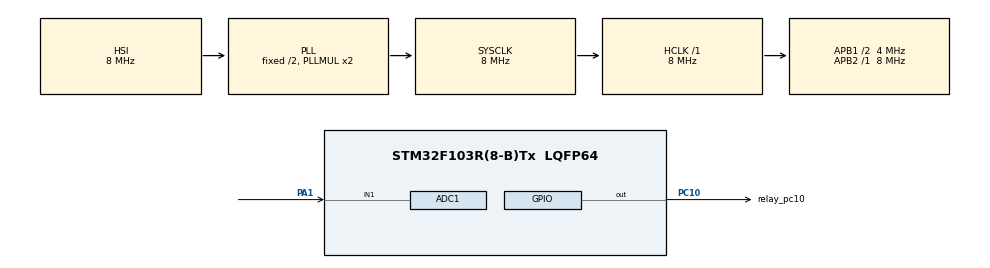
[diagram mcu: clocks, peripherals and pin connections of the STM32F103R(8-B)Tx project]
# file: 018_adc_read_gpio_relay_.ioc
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ADC1.Channel-0\#ChannelRegularConversion=ADC_CHANNEL_1
ADC1.NbrOfConversionFlag=1
ADC1.Rank-0\#ChannelRegularConversion=1
ADC1.SamplingTime-0\#ChannelRegularConversion=ADC_SAMPLETIME_1CYCLE_5
ADC1.master=1
Mcu.Family=STM32F1
Mcu.Name=STM32F103R(8-B)Tx
Mcu.Package=LQFP64
NVIC.PriorityGroup=NVIC_PRIORITYGROUP_4
PA1.Signal=ADCx_IN1
PA13.GPIO_Label=TMS
PA13.Mode=Serial_Wire
PA13.Signal=SYS_JTMS-SWDIO
PA14.GPIO_Label=TCK
PA14.Mode=Serial_Wire
PA14.Signal=SYS_JTCK-SWCLK
PB3.GPIO_Label=SWO
PB3.Signal=SYS_JTDO-TRACESWO
PC10.GPIO_Label=relay_pc10
PC10.GPIO_ModeDefaultOutputPP=GPIO_MODE_OUTPUT_OD
PC10.GPIO_PuPd=GPIO_NOPULL
PC10.Signal=GPIO_Output
PC14-OSC32_IN.Mode=LSE-External-Oscillator
PC14-OSC32_IN.Signal=RCC_OSC32_IN
PC15-OSC32_OUT.Mode=LSE-External-Oscillator
PC15-OSC32_OUT.Signal=RCC_OSC32_OUT
PD0-OSC_IN.Mode=HSE-External-Clock-Source
PD0-OSC_IN.Signal=RCC_OSC_IN
PD1-OSC_OUT.Mode=HSE-External-Clock-Source
PD1-OSC_OUT.Signal=RCC_OSC_OUT
ProjectManager.HeapSize=0x200
ProjectManager.StackSize=0x400
ProjectManager.TargetToolchain=STM32CubeIDE
RCC.AHBFreq_Value=8000000
RCC.APB1CLKDivider=RCC_HCLK_DIV2
RCC.APB1Freq_Value=4000000
RCC.APB1TimFreq_Value=8000000
RCC.APB2Freq_Value=8000000
RCC.APB2TimFreq_Value=8000000
RCC.HCLKFreq_Value=8000000
RCC.RTCClockSelection=RCC_RTCCLKSOURCE_LSE
RCC.SYSCLKFreq_VALUE=8000000
RCC.SYSCLKSource=RCC_SYSCLKSOURCE_PLLCLK
RCC.USBFreq_Value=8000000
SH.ADCx_IN1.0=ADC1_IN1,IN1
board=NUCLEO-F103RB

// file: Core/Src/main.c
/* USER CODE BEGIN Header */
/**
  ******************************************************************************
  * @file           : main.c
  * @brief          : Main program body
  ******************************************************************************
  * @attention
  *
  * Copyright (c) 2025 STMicroelectronics.
  * All rights reserved.
  *
  * This software is licensed under terms that can be found in the LICENSE file
  * in the root directory of this software component.
  * If no LICENSE file comes with this software, it is provided AS-IS.
  *
  ******************************************************************************
  */
/* USER CODE END Header */
#include "main.h"

/* USER CODE BEGIN Includes */

// Constants for 4-20mA sensor
#define SHUNT_RESISTOR 100.0f     // Shunt resistor value in ohms
#define ADC_RESOLUTION 4096.0f   // 12-bit ADC
#define VREF 5.0f                // ADC reference voltage in volts
#define TEMP_MIN 23.0f            // Minimum temperature (°C)
#define TEMP_MAX 200.0f          // Maximum temperature (°C)

/* USER CODE END Includes */

ADC_HandleTypeDef hadc1;

void SystemClock_Config(void);
static void MX_GPIO_Init(void);
static void MX_ADC1_Init(void);

/* USER CODE BEGIN 0 */
// Constants

/* USER CODE END 0 */

int main(void)
{

  /* USER CODE BEGIN 1 */
	volatile uint32_t adc_value;

  /* USER CODE END 1 */

  /* MCU Configuration--------------------------------------------------------*/

  /* Reset of all peripherals, Initializes the Flash interface and the Systick. */
  HAL_Init();

  /* Configure the system clock */
  SystemClock_Config();

  /* Initialize all configured peripherals */
  MX_GPIO_Init();
  MX_ADC1_Init();
  /* USER CODE BEGIN 2 */
  HAL_ADC_Start(&hadc1);
  /* USER CODE END 2 */

  /* Infinite loop */
  while (1)
  {
	  // Poll for ADC conversion
	  HAL_ADC_PollForConversion(&hadc1, 100);
	  adc_value = HAL_ADC_GetValue(&hadc1);

	  printf("adc_value== %lu\n",adc_value);
	  fflush(stdout);
	 	  //HAL_Delay(4000);

	        // Convert ADC value to voltage
	        float measured_voltage = (adc_value * VREF) / ADC_RESOLUTION;

	        // Calculate current (I = V / R)
	        float current = measured_voltage / SHUNT_RESISTOR; // Current in Amps

	        // Map current to temperature
	        float temperature = TEMP_MIN + ((current - 0.004f) / 0.016f) * (TEMP_MAX - TEMP_MIN);

	        // Print temperature, current, and voltage
	        printf("Measured Voltage: %.2f V, Current: %.2f mA, Temperature: %.2f °C\n",
	               measured_voltage, current * 1000.0f, temperature + 2.0 );
	        fflush(stdout);

	        if(temperature > 60 && temperature<90){

	        	HAL_GPIO_WritePin(GPIOC, GPIO_PIN_10, GPIO_PIN_SET );
	        	HAL_GPIO_TogglePin(GPIOC, GPIO_PIN_10);
	        }
	        else{
	         	HAL_GPIO_WritePin(GPIOC, GPIO_PIN_10, GPIO_PIN_RESET );
	        }

	        HAL_Delay(7000); // Delay for 1 second

  }
}

void SystemClock_Config(void)
{
  RCC_OscInitTypeDef RCC_OscInitStruct = {0};
  RCC_ClkInitTypeDef RCC_ClkInitStruct = {0};
  RCC_PeriphCLKInitTypeDef PeriphClkInit = {0};

  /** Initializes the RCC Oscillators according to the specified parameters
  * in the RCC_OscInitTypeDef structure.
  */
  RCC_OscInitStruct.OscillatorType = RCC_OSCILLATORTYPE_HSI;
  RCC_OscInitStruct.HSIState = RCC_HSI_ON;
  RCC_OscInitStruct.HSICalibrationValue = RCC_HSICALIBRATION_DEFAULT;
  RCC_OscInitStruct.PLL.PLLState = RCC_PLL_ON;
  RCC_OscInitStruct.PLL.PLLSource = RCC_PLLSOURCE_HSI_DIV2;
  RCC_OscInitStruct.PLL.PLLMUL = RCC_PLL_MUL2;
  if (HAL_RCC_OscConfig(&RCC_OscInitStruct) != HAL_OK)
  {
    Error_Handler();
  }

  /** Initializes the CPU, AHB and APB buses clocks
  */
  RCC_ClkInitStruct.ClockType = RCC_CLOCKTYPE_HCLK|RCC_CLOCKTYPE_SYSCLK
                              |RCC_CLOCKTYPE_PCLK1|RCC_CLOCKTYPE_PCLK2;
  RCC_ClkInitStruct.SYSCLKSource = RCC_SYSCLKSOURCE_PLLCLK;
  RCC_ClkInitStruct.AHBCLKDivider = RCC_SYSCLK_DIV1;
  RCC_ClkInitStruct.APB1CLKDivider = RCC_HCLK_DIV2;
  RCC_ClkInitStruct.APB2CLKDivider = RCC_HCLK_DIV1;

  if (HAL_RCC_ClockConfig(&RCC_ClkInitStruct, FLASH_LATENCY_0) != HAL_OK)
  {
    Error_Handler();
  }
  PeriphClkInit.PeriphClockSelection = RCC_PERIPHCLK_ADC;
  PeriphClkInit.AdcClockSelection = RCC_ADCPCLK2_DIV2;
  if (HAL_RCCEx_PeriphCLKConfig(&PeriphClkInit) != HAL_OK)
  {
    Error_Handler();
  }
}

static void MX_ADC1_Init(void)
{

  ADC_ChannelConfTypeDef sConfig = {0};

  /** Common config
  */
  hadc1.Instance = ADC1;
  hadc1.Init.ScanConvMode = ADC_SCAN_DISABLE;
  hadc1.Init.ContinuousConvMode = DISABLE;
  hadc1.Init.DiscontinuousConvMode = DISABLE;
  hadc1.Init.ExternalTrigConv = ADC_SOFTWARE_START;
  hadc1.Init.DataAlign = ADC_DATAALIGN_RIGHT;
  hadc1.Init.NbrOfConversion = 1;
  if (HAL_ADC_Init(&hadc1) != HAL_OK)
  {
    Error_Handler();
  }

  /** Configure Regular Channel
  */
  sConfig.Channel = ADC_CHANNEL_1;
  sConfig.Rank = ADC_REGULAR_RANK_1;
  sConfig.SamplingTime = ADC_SAMPLETIME_1CYCLE_5;
  if (HAL_ADC_ConfigChannel(&hadc1, &sConfig) != HAL_OK)
  {
    Error_Handler();
  }

}

static void MX_GPIO_Init(void)
{
  GPIO_InitTypeDef GPIO_InitStruct = {0};

  /* GPIO Ports Clock Enable */
  __HAL_RCC_GPIOC_CLK_ENABLE();
  __HAL_RCC_GPIOD_CLK_ENABLE();
  __HAL_RCC_GPIOA_CLK_ENABLE();
  __HAL_RCC_GPIOB_CLK_ENABLE();

  /*Configure GPIO pin Output Level */
  HAL_GPIO_WritePin(relay_pc10_GPIO_Port, relay_pc10_Pin, GPIO_PIN_RESET);

  /*Configure GPIO pin : relay_pc10_Pin */
  GPIO_InitStruct.Pin = relay_pc10_Pin;
  GPIO_InitStruct.Mode = GPIO_MODE_OUTPUT_OD;
  GPIO_InitStruct.Pull = GPIO_NOPULL;
  GPIO_InitStruct.Speed = GPIO_SPEED_FREQ_LOW;
  HAL_GPIO_Init(relay_pc10_GPIO_Port, &GPIO_InitStruct);

}

void Error_Handler(void)
{
  __disable_irq();
  while (1)
  {
  }
}
